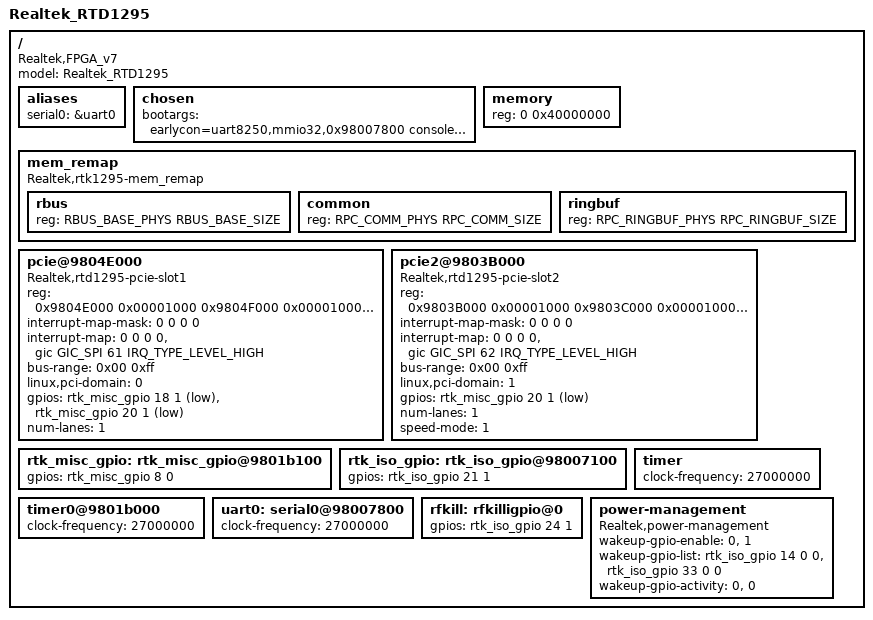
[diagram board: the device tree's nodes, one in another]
/dts-v1/;
#define CONFIG_ARCH_RTD129X
#include "../../../../../include/soc/realtek/memory.h"

/memreserve/ SYS_BOOTCODE_MEMBASE       SYS_BOOTCODE_MEMSIZE        ; /* 0x00000000 ~ 0x00030000 */
/memreserve/ RPC_COMM_PHYS              RPC_COMM_SIZE               ; /* 0x0001f000 ~ 0x001fffff */
/memreserve/ ACPU_FIREWARE_PHYS         ACPU_FIREWARE_SIZE          ; /* 0x01b00000 ~ 0x01efffff */
/memreserve/ RPC_RINGBUF_PHYS           RPC_RINGBUF_SIZE            ; /* 0x01ffe000 ~ 0x02001fff */
/memreserve/ ACPU_IDMEM_PHYS            ACPU_IDMEM_SIZE             ; /* 0x10000000 ~ 0x10013fff */
/memreserve/ ACPU_BOOTCODE_PHYS         ACPU_BOOTCODE_SIZE          ; /* 0x10000000 ~ 0x10013fff */

#include "rtd-1295.dtsi"
#include "rtd-129x-dvfs.dtsi"

/ {
	model= "Realtek_RTD1295";
	compatible = "Realtek,FPGA_v7", "Realtek,rtd-1295";

	aliases {
		serial0 = &uart0;
	};

	chosen {
		bootargs = "earlycon=uart8250,mmio32,0x98007800 console=ttyS0,115200 loglevel=7";
	};

	memory {
		device_type = "memory";
		reg = <0 0x40000000>;	/* 1024 MB */
	};

	mem_remap {
		compatible = "Realtek,rtk1295-mem_remap";
		#address-cells = <1>;
		#size-cells = <1>;
		ranges;
		rbus {
			reg = <RBUS_BASE_PHYS RBUS_BASE_SIZE>;
		};
		common {
			reg = <RPC_COMM_PHYS RPC_COMM_SIZE>;
		};
		ringbuf {
			reg = <RPC_RINGBUF_PHYS RPC_RINGBUF_SIZE>;
		};
	};

	pcie@9804E000 {
		compatible = "Realtek,rtd1295-pcie-slot1";
		reg = <0x9804E000 0x00001000
		       0x9804F000 0x00001000
		       0x9801C600 0x00000100
		       0x9801A000 0x00000300
		       0x98012000 0x00001000>;
		interrupt-names = "rtk-pcie1-intr";
		#interrupt-cells = <1>;
		interrupt-map-mask = <0 0 0 0>;
		interrupt-map = <0 0 0 0 &gic GIC_SPI 61 IRQ_TYPE_LEVEL_HIGH>;
		bus-range = <0x00 0xff>;
		linux,pci-domain = <0>;
		device_type = "pci";
		gpios = <&rtk_misc_gpio 18 1 1 >, <&rtk_misc_gpio 20 1 1>;
		#size-cells = <2>;
		#address-cells = <3>;
		num-lanes = <1>;
		ranges = <0x02000000 0x00000000 0xC0000000  0xC0000000 0x00000000 0x01000000
			  0x01000000 0x00000000 0x00030000  0x00030000 0x00000000 0x00010000>;
		status = "okay";
	};

	pcie2@9803B000 {
		compatible = "Realtek,rtd1295-pcie-slot2";
		reg = <0x9803B000 0x00001000
		       0x9803C000 0x00001000
		       0x9801C600 0x00000100
		       0x9801A000 0x00000300
		       0x98012000 0x00001000>;
		interrupt-names = "rtk-pcie2-intr";
		#interrupt-cells = <1>;
		interrupt-map-mask = <0 0 0 0>;
		interrupt-map = <0 0 0 0 &gic GIC_SPI 62 IRQ_TYPE_LEVEL_HIGH>;
		bus-range = <0x00 0xff>;
		linux,pci-domain = <1>;
		device_type = "pci";
		gpios = <&rtk_misc_gpio 20 1 1>;
		#size-cells = <2>;
		#address-cells = <3>;
		num-lanes = <1>;
		ranges = <0x02000000 0x00000000 0xC1000000  0xC1000000 0x00000000 0x01000000
			  0x01000000 0x00000000 0x00040000  0x00040000 0x00000000 0x00010000>;
		speed-mode = <1>; // 0:GEN1, 1:GEN2
		status = "okay";
	};

	rtk_misc_gpio: rtk_misc_gpio@9801b100 {
		gpios = <&rtk_misc_gpio 8 0 0>;
		/* install button, input, default N/A */
	};

	rtk_iso_gpio: rtk_iso_gpio@98007100 {
		gpios = <&rtk_iso_gpio 21 1 0>;
		/* igpio21, output, default low */
	};

	timer {
		clock-frequency = <27000000>;
	};

	timer0@9801b000 {
		clock-frequency = <27000000>;
	};

	uart0: serial0@98007800 {
		clock-frequency = <27000000>;
	};

	rfkill: rfkilligpio@0{
		gpios = <&rtk_iso_gpio 24 1 0>;                         /*bt power , output, default low */
		status = "okay";
	};

	power-management{
		compatible = "Realtek,power-management";

		/* GPIO Wakeup */
		wakeup-gpio-enable = /* (0) disable (1) enable */
			<0>, /* Wakeup from BT : disable */
			<1>; /* Wakeup from WiFi : disable */
		wakeup-gpio-list = /* <&rtk_iso_gpio {num} {force input (0) } {default N/A (0)] }> */
			<&rtk_iso_gpio 14 0 0>, /* BT wakeup host pin */
			<&rtk_iso_gpio 33 0 0>; /* WiFi wakeup host pin */
		wakeup-gpio-activity = /* (0) active low (1) active high*/
			<0>, /* BT : high activity */
			<0>; /* Wifi : high activity */
	};
};
